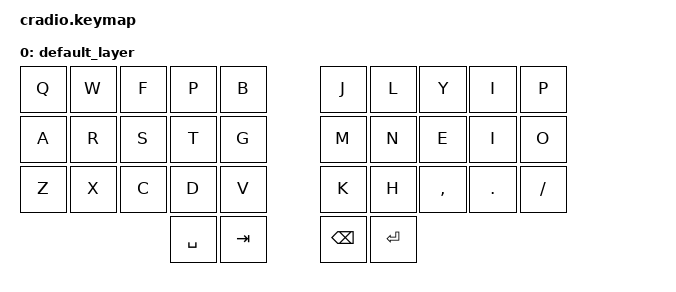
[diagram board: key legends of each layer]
/*
 * Copyright (c) 2020 The ZMK Contributors
 *
 * SPDX-License-Identifier: MIT
 */

#include <behaviors.dtsi>
#include <dt-bindings/zmk/keys.h>
#include <dt-bindings/zmk/bt.h>


&kscan0 {
	input-gpios
	= <&pro_micro_d  6 (GPIO_ACTIVE_LOW | GPIO_PULL_UP)>
	, <&pro_micro_a  0 (GPIO_ACTIVE_LOW | GPIO_PULL_UP)>
	, <&pro_micro_a  1 (GPIO_ACTIVE_LOW | GPIO_PULL_UP)>
	, <&pro_micro_a  2 (GPIO_ACTIVE_LOW | GPIO_PULL_UP)>
	, <&pro_micro_a  3 (GPIO_ACTIVE_LOW | GPIO_PULL_UP)>
	, <&pro_micro_d 15 (GPIO_ACTIVE_LOW | GPIO_PULL_UP)>
	, <&pro_micro_d 14 (GPIO_ACTIVE_LOW | GPIO_PULL_UP)>
	, <&pro_micro_d 16 (GPIO_ACTIVE_LOW | GPIO_PULL_UP)>
	, <&pro_micro_d 10 (GPIO_ACTIVE_LOW | GPIO_PULL_UP)>
	, <&pro_micro_d  1 (GPIO_ACTIVE_LOW | GPIO_PULL_UP)>
	, <&pro_micro_d  2 (GPIO_ACTIVE_LOW | GPIO_PULL_UP)>
	, <&pro_micro_d  3 (GPIO_ACTIVE_LOW | GPIO_PULL_UP)>
	, <&pro_micro_d  4 (GPIO_ACTIVE_LOW | GPIO_PULL_UP)>
	, <&pro_micro_d  5 (GPIO_ACTIVE_LOW | GPIO_PULL_UP)>
	, <&pro_micro_d  7 (GPIO_ACTIVE_LOW | GPIO_PULL_UP)>
	, <&pro_micro_d  8 (GPIO_ACTIVE_LOW | GPIO_PULL_UP)>
	, <&pro_micro_d  9 (GPIO_ACTIVE_LOW | GPIO_PULL_UP)>
	;
};


/ { 

    keymap {
		compatible = "zmk,keymap";
			
		default_layer {
			bindings = <
			&kp Q &kp W &kp F &kp P &kp B 				   &kp J &kp L  &kp Y &kp I &kp P 
			&kp A &kp R &kp S &kp T &kp G 			       &kp M &kp N  &kp E &kp I &kp O
			&kp Z &kp X &kp C &kp D &kp V				   &kp K &kp H  &kp CMMA &kp DOT &kp FSLH
							  &kp SPC 1 &kp TAB  		&kp BKSP &kp RET 
			>;
		};
	};
};
